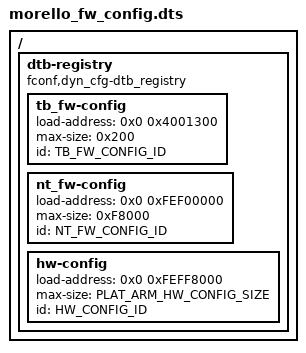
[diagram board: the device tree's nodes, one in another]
/*
 * Copyright (c) 2021-2024, Arm Limited. All rights reserved.
 *
 * SPDX-License-Identifier: BSD-3-Clause
 */

#include <common/tbbr/tbbr_img_def.h>
#include <platform_def.h>

/dts-v1/;
/ {
	dtb-registry {
		compatible = "fconf,dyn_cfg-dtb_registry";

		tb_fw-config {
			load-address = <0x0 0x4001300>;
			max-size = <0x200>;
			id = <TB_FW_CONFIG_ID>;
		};

		nt_fw-config {
			load-address = <0x0 0xFEF00000>;
			max-size = <0xF8000>;
			id = <NT_FW_CONFIG_ID>;
		};

		hw-config {
			load-address = <0x0 0xFEFF8000>;
			max-size = <PLAT_ARM_HW_CONFIG_SIZE>;
			id = <HW_CONFIG_ID>;
		};
	};
};
